# MDR32F8 register map
Vendor: Milandr; File version: 1.0
CPU: CM4 r1p1, little endian, no MPU, FPU, 3 interrupt priority bits
Registers are 32-bit, read-write, reset 0x0 unless marked. A register's access mark holds for its fields unless they carry their own. Offsets are from the block's base; [hi:lo] are bit positions; {n}, {i} and the like mark numbered series; 'fields as' and 'values as' point back to an identical list.

## MDR_CLK — Clock controll registers
Base 0x40000000; register names take the prefix MDR_CLK
0x00 KEY — Key lock Register
0x04 MAX_CLK
  [3:0] SELECT
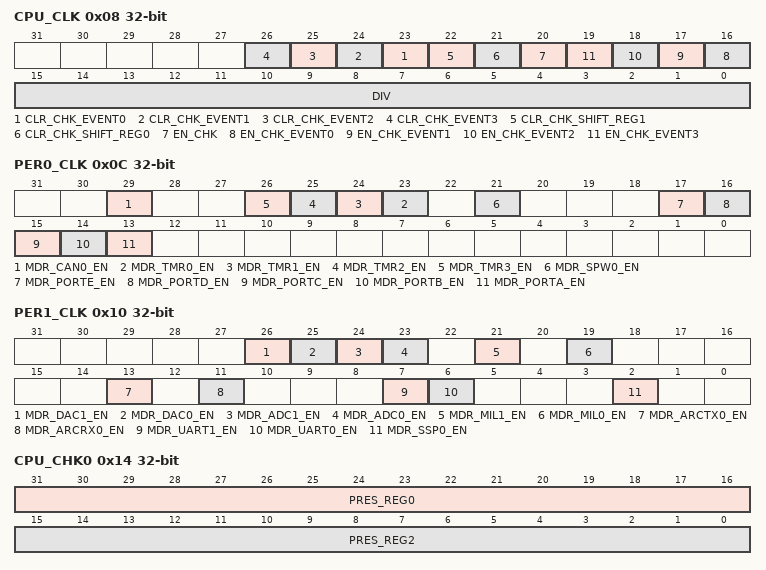
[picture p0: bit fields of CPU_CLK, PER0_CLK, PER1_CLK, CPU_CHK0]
0x08 CPU_CLK — CPU clock Register
  [n+23] CLR_CHK_EVENT{n} (n=0..3), [22] CLR_CHK_SHIFT_REG1, [21] CLR_CHK_SHIFT_REG0, [20] EN_CHK, [n+16] EN_CHK_EVENT{n} (n=0..3), [15:0] DIV
0x0C PER0_CLK — Pherepherial clock Register
  [29] MDR_CAN0_EN, [n+23] MDR_TMR{n}_EN (n=0..3), [21] MDR_SPW0_EN, [17] MDR_PORTE_EN, [16] MDR_PORTD_EN, [15] MDR_PORTC_EN, [14] MDR_PORTB_EN, [13] MDR_PORTA_EN
0x10 PER1_CLK
  [26] MDR_DAC1_EN, [25] MDR_DAC0_EN, [24] MDR_ADC1_EN, [23] MDR_ADC0_EN, [21] MDR_MIL1_EN, [19] MDR_MIL0_EN, [13] MDR_ARCTX0_EN, [11] MDR_ARCRX0_EN, [7] MDR_UART1_EN, [6] MDR_UART0_EN, [2] MDR_SSP0_EN
0x14 CPU_CHK0
  [31:16] PRES_REG0, [15:0] PRES_REG2
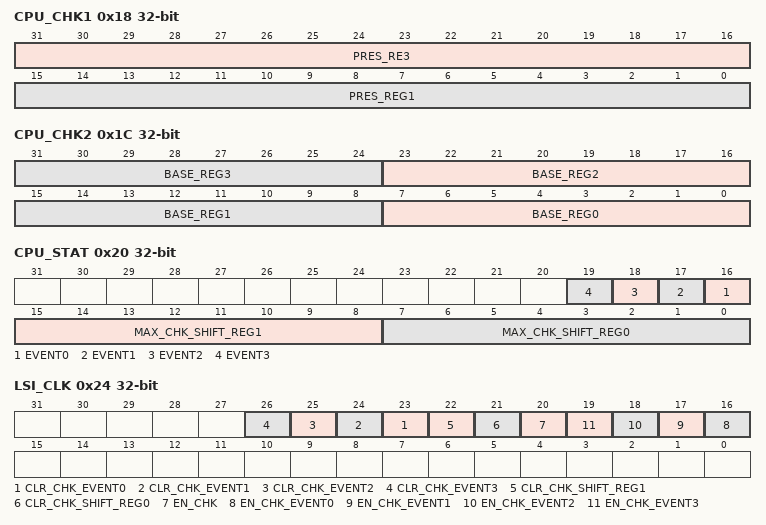
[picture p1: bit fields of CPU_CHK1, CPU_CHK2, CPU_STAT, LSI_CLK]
0x18 CPU_CHK1
  [31:16] PRES_RE3, [15:0] PRES_REG1
0x1C CPU_CHK2
  [8n+7:8n] BASE_REG{n} (n=0..3)
0x20 CPU_STAT ro — Status Register clock system
  [n+16] EVENT{n} (n=0..3), [15:8] MAX_CHK_SHIFT_REG1, [7:0] MAX_CHK_SHIFT_REG0
0x24 LSI_CLK
  [n+23] CLR_CHK_EVENT{n} (n=0..3), [22] CLR_CHK_SHIFT_REG1, [21] CLR_CHK_SHIFT_REG0, [20] EN_CHK, [n+16] EN_CHK_EVENT{n} (n=0..3)
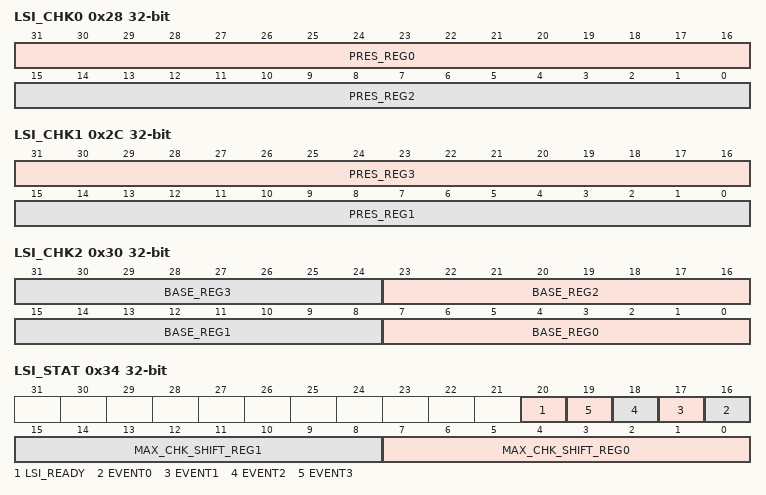
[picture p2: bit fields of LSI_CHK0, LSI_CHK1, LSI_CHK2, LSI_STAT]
0x28 LSI_CHK0
  [31:16] PRES_REG0, [15:0] PRES_REG2
0x2C LSI_CHK1
  [31:16] PRES_REG3, [15:0] PRES_REG1
0x30 LSI_CHK2
  [8n+7:8n] BASE_REG{n} (n=0..3)
0x34 LSI_STAT ro — LSI Status Register
  [20] LSI_READY, [n+16] EVENT{n} (n=0..3), [15:8] MAX_CHK_SHIFT_REG1, [7:0] MAX_CHK_SHIFT_REG0
0x38 HSI_STAT ro — HSI Status Register
  [20] HSI_READY
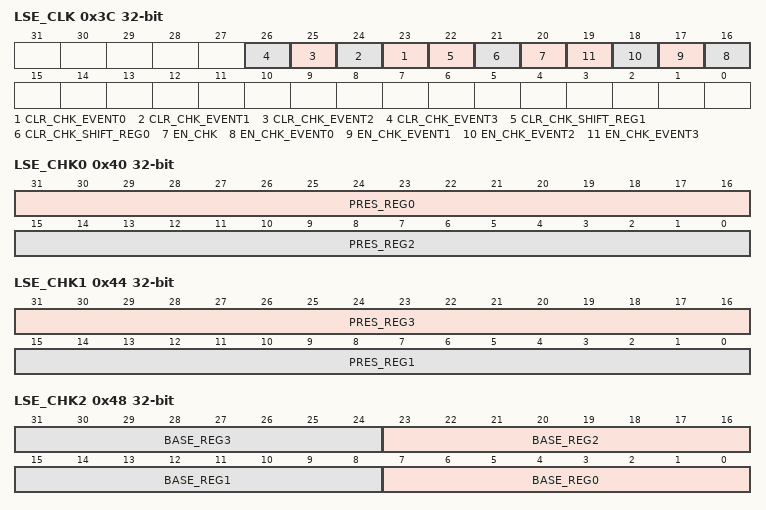
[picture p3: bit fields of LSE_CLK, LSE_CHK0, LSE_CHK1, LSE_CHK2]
0x3C LSE_CLK
  fields as LSI_CLK
0x40 LSE_CHK0
  [31:16] PRES_REG0, [15:0] PRES_REG2
0x44 LSE_CHK1
  [31:16] PRES_REG3, [15:0] PRES_REG1
0x48 LSE_CHK2
  [8n+7:8n] BASE_REG{n} (n=0..3)
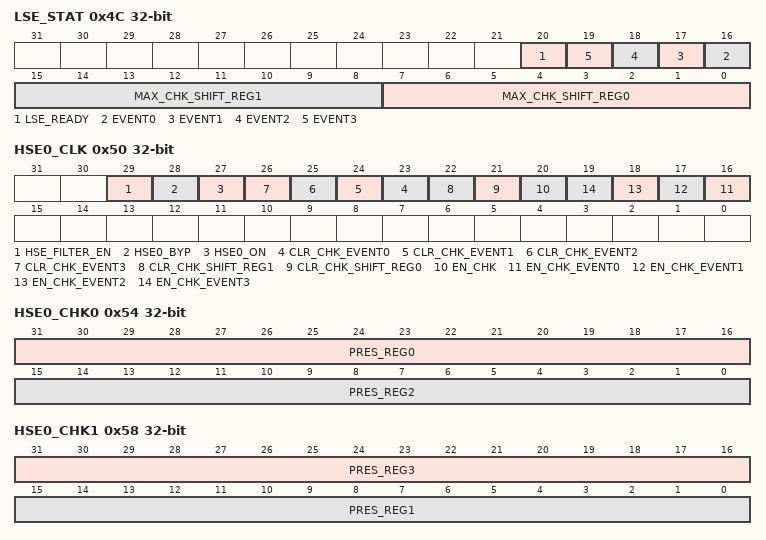
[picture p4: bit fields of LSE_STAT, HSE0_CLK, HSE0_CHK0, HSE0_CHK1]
0x4C LSE_STAT ro — LSE Status Register
  [20] LSE_READY, [n+16] EVENT{n} (n=0..3), [15:8] MAX_CHK_SHIFT_REG1, [7:0] MAX_CHK_SHIFT_REG0
0x50 HSE0_CLK
  [29] HSE_FILTER_EN, [28] HSE0_BYP, [27] HSE0_ON, [n+23] CLR_CHK_EVENT{n} (n=0..3), [22] CLR_CHK_SHIFT_REG1, [21] CLR_CHK_SHIFT_REG0, [20] EN_CHK, [n+16] EN_CHK_EVENT{n} (n=0..3)
0x54 HSE0_CHK0
  [31:16] PRES_REG0, [15:0] PRES_REG2
0x58 HSE0_CHK1
  [31:16] PRES_REG3, [15:0] PRES_REG1
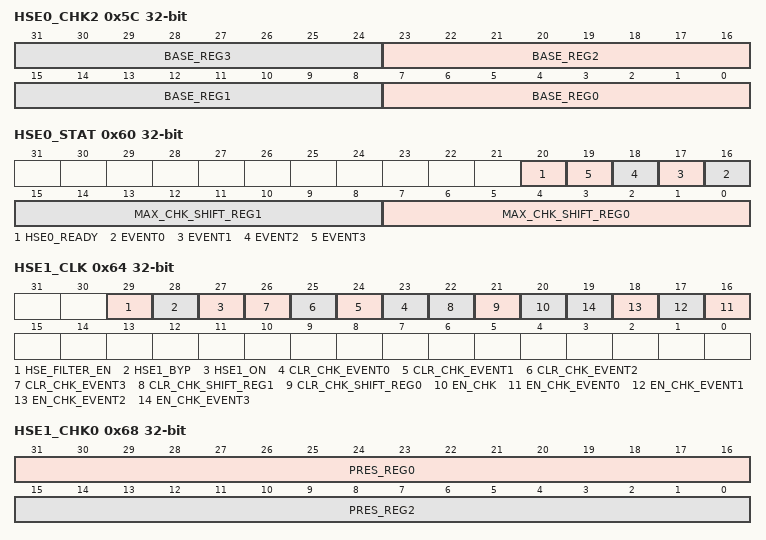
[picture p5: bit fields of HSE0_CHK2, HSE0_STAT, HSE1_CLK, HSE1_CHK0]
0x5C HSE0_CHK2
  [8n+7:8n] BASE_REG{n} (n=0..3)
0x60 HSE0_STAT ro — HSE0 Status Register
  [20] HSE0_READY, [n+16] EVENT{n} (n=0..3), [15:8] MAX_CHK_SHIFT_REG1, [7:0] MAX_CHK_SHIFT_REG0
0x64 HSE1_CLK
  [29] HSE_FILTER_EN, [28] HSE1_BYP, [27] HSE1_ON, [n+23] CLR_CHK_EVENT{n} (n=0..3), [22] CLR_CHK_SHIFT_REG1, [21] CLR_CHK_SHIFT_REG0, [20] EN_CHK, [n+16] EN_CHK_EVENT{n} (n=0..3)
0x68 HSE1_CHK0
  [31:16] PRES_REG0, [15:0] PRES_REG2
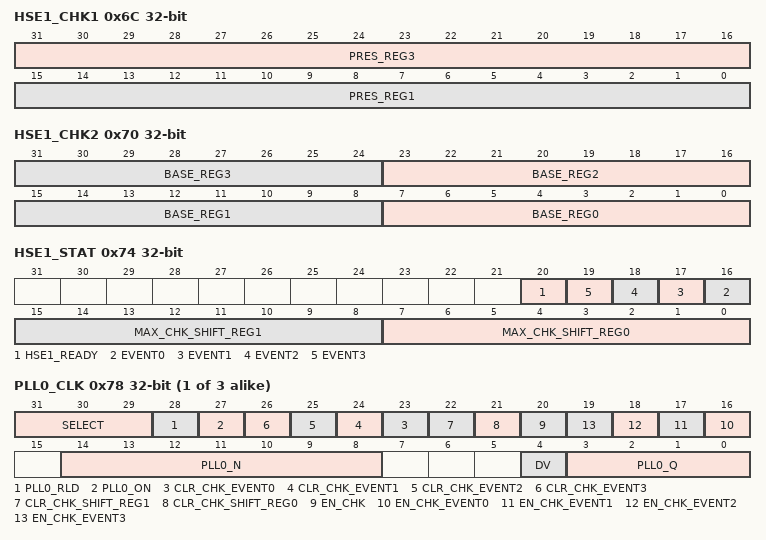
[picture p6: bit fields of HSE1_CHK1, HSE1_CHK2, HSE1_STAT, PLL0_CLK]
0x6C HSE1_CHK1
  [31:16] PRES_REG3, [15:0] PRES_REG1
0x70 HSE1_CHK2
  [8n+7:8n] BASE_REG{n} (n=0..3)
0x74 HSE1_STAT ro — HSE1 Status Register
  [20] HSE1_READY, [n+16] EVENT{n} (n=0..3), [15:8] MAX_CHK_SHIFT_REG1, [7:0] MAX_CHK_SHIFT_REG0
{0x78+0x14*i} PLL{i}_CLK (i=0..2)
  [31:29] SELECT, [28] PLL{i}_RLD, [27] PLL{i}_ON, [n+23] CLR_CHK_EVENT{n} (n=0..3), [22] CLR_CHK_SHIFT_REG1, [21] CLR_CHK_SHIFT_REG0, [20] EN_CHK, [n+16] EN_CHK_EVENT{n} (n=0..3), [14:8] PLL{i}_N, [4] DV, [3:0] PLL{i}_Q
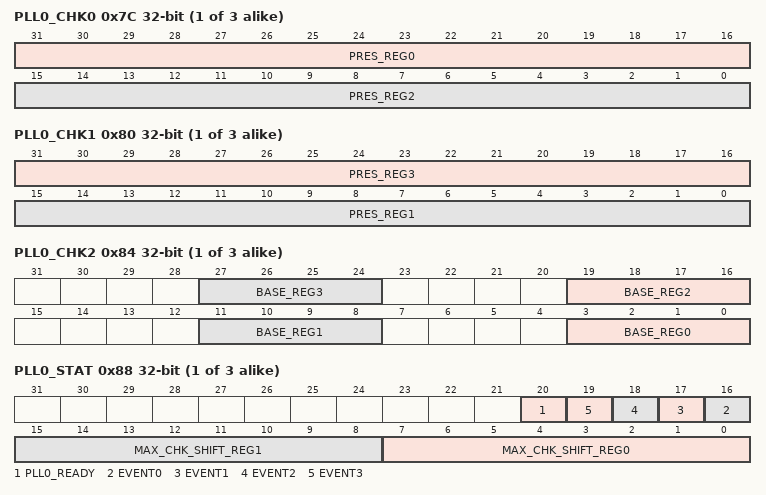
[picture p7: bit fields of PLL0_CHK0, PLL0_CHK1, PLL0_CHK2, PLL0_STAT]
{0x7C+0x14*i} PLL{i}_CHK0 (i=0..2)
  [31:16] PRES_REG0, [15:0] PRES_REG2
{0x80+0x14*i} PLL{i}_CHK1 (i=0..2)
  [31:16] PRES_REG3, [15:0] PRES_REG1
{0x84+0x14*i} PLL{i}_CHK2 (i=0..2)
  [8n+3:8n] BASE_REG{n} (n=0..3)
{0x88+0x14*i} PLL{i}_STAT ro (i=0..2) — PLL{i} Status Register
  [20] PLL{i}_READY, [n+16] EVENT{n} (n=0..3), [15:8] MAX_CHK_SHIFT_REG1, [7:0] MAX_CHK_SHIFT_REG0
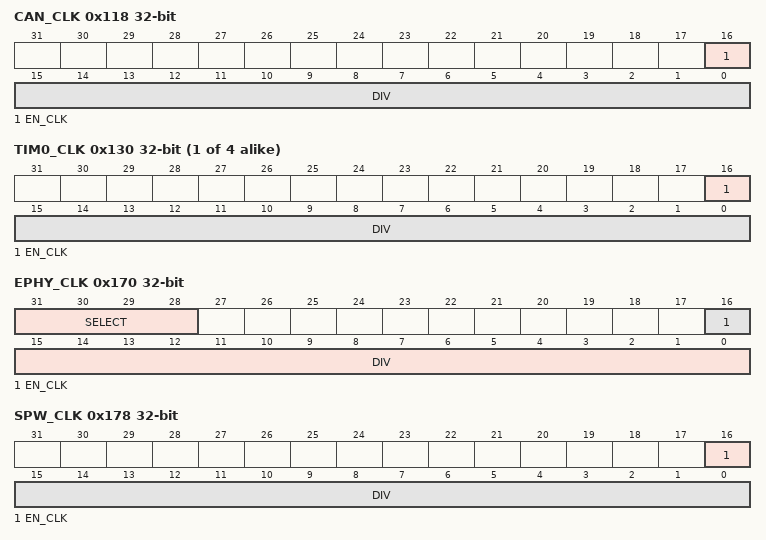
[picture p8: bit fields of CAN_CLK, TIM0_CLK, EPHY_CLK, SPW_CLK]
0x118 CAN_CLK
  [16] EN_CLK, [15:0] DIV
{0x130+4i} TIM{i}_CLK (i=0..3)
  [16] EN_CLK, [15:0] DIV
0x170 EPHY_CLK
  [31:28] SELECT, [16] EN_CLK, [15:0] DIV
0x178 SPW_CLK
  [16] EN_CLK, [15:0] DIV
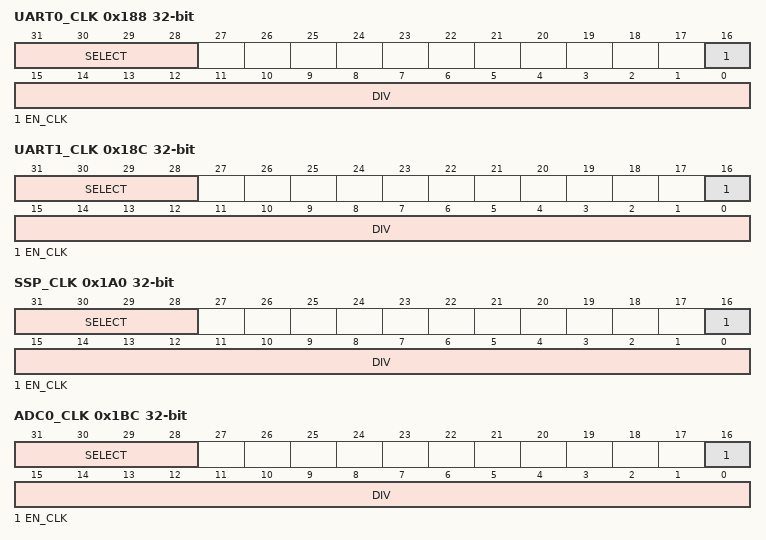
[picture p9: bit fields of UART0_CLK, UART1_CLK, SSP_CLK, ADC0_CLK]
0x188 UART0_CLK
  [31:28] SELECT, [16] EN_CLK, [15:0] DIV
0x18C UART1_CLK
  [31:28] SELECT, [16] EN_CLK, [15:0] DIV
0x1A0 SSP_CLK
  [31:28] SELECT, [16] EN_CLK, [15:0] DIV
0x1BC ADC0_CLK
  [31:28] SELECT, [16] EN_CLK, [15:0] DIV
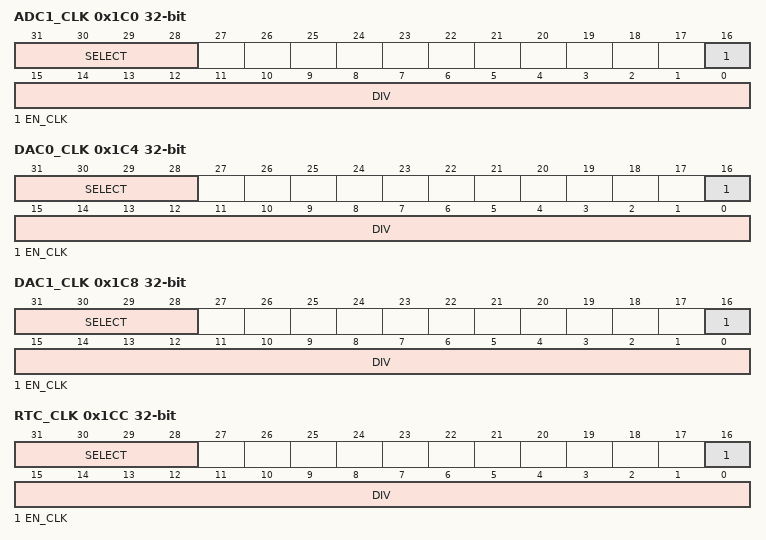
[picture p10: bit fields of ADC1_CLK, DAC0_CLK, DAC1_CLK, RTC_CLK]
0x1C0 ADC1_CLK
  [31:28] SELECT, [16] EN_CLK, [15:0] DIV
0x1C4 DAC0_CLK
  [31:28] SELECT, [16] EN_CLK, [15:0] DIV
0x1C8 DAC1_CLK
  [31:28] SELECT, [16] EN_CLK, [15:0] DIV
0x1CC RTC_CLK
  [31:28] SELECT, [16] EN_CLK, [15:0] DIV
